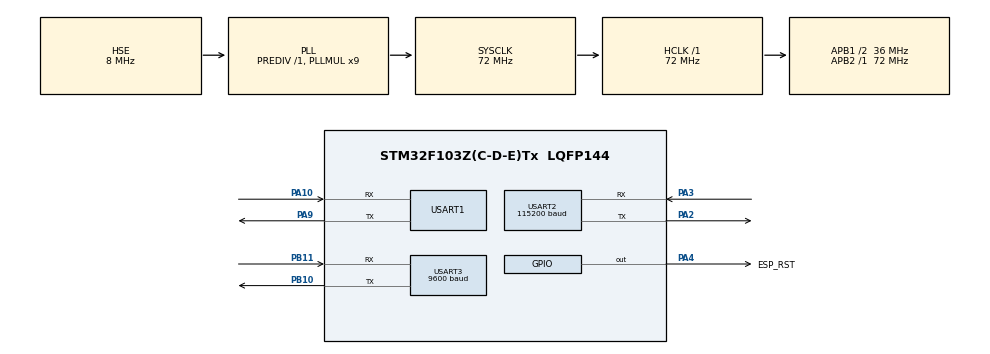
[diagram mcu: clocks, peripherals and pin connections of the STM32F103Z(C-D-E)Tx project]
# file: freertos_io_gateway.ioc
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FREERTOS.Tasks01=mbMasterTask,24,256,StartModbusMasterTask,As weak,NULL,Dynamic,NULL,NULL;mbRxTask,32,256,StartModbusRxTask,As external,NULL,Dynamic,NULL,NULL
Mcu.Family=STM32F1
Mcu.Name=STM32F103Z(C-D-E)Tx
Mcu.Package=LQFP144
NVIC.PriorityGroup=NVIC_PRIORITYGROUP_4
NVIC.TIM2_IRQn=true\:5\:0\:true\:false\:true\:true\:true\:true\:true
NVIC.TIM3_IRQn=true\:15\:0\:false\:false\:true\:false\:false\:true\:true
NVIC.TimeBase=TIM3_IRQn
NVIC.TimeBaseIP=TIM3
NVIC.USART2_IRQn=true\:5\:0\:true\:false\:true\:true\:true\:true\:true
NVIC.USART3_IRQn=true\:5\:0\:true\:false\:true\:true\:true\:true\:true
OSC_IN.Mode=HSE-External-Oscillator
OSC_IN.Signal=RCC_OSC_IN
OSC_OUT.Mode=HSE-External-Oscillator
OSC_OUT.Signal=RCC_OSC_OUT
PA10.Mode=Asynchronous
PA10.Signal=USART1_RX
PA13.Mode=Serial_Wire
PA13.Signal=SYS_JTMS-SWDIO
PA14.Mode=Serial_Wire
PA14.Signal=SYS_JTCK-SWCLK
PA2.Mode=Asynchronous
PA2.Signal=USART2_TX
PA3.Mode=Asynchronous
PA3.Signal=USART2_RX
PA4.GPIO_Label=ESP_RST
PA4.PinState=GPIO_PIN_SET
PA4.Signal=GPIO_Output
PA9.Mode=Asynchronous
PA9.Signal=USART1_TX
PB10.Mode=Asynchronous
PB10.Signal=USART3_TX
PB11.Mode=Asynchronous
PB11.Signal=USART3_RX
PC14-OSC32_IN.Mode=LSE-External-Oscillator
PC14-OSC32_IN.Signal=RCC_OSC32_IN
PC15-OSC32_OUT.Mode=LSE-External-Oscillator
PC15-OSC32_OUT.Signal=RCC_OSC32_OUT
ProjectManager.HeapSize=0x200
ProjectManager.StackSize=0x400
ProjectManager.TargetToolchain=CMake
RCC.AHBFreq_Value=72000000
RCC.APB1CLKDivider=RCC_HCLK_DIV2
RCC.APB1Freq_Value=36000000
RCC.APB1TimFreq_Value=72000000
RCC.APB2Freq_Value=72000000
RCC.APB2TimFreq_Value=72000000
RCC.HCLKFreq_Value=72000000
RCC.PLLMUL=RCC_PLL_MUL9
RCC.PLLSourceVirtual=RCC_PLLSOURCE_HSE
RCC.SYSCLKFreq_VALUE=72000000
RCC.SYSCLKSource=RCC_SYSCLKSOURCE_PLLCLK
RCC.USBFreq_Value=72000000
TIM2.Period=999
TIM2.Prescaler=71
USART1.VirtualMode=VM_ASYNC
USART2.BaudRate=115200
USART2.VirtualMode=VM_ASYNC
USART3.BaudRate=9600
USART3.VirtualMode=VM_ASYNC
VP_FREERTOS_VS_CMSIS_V2.Mode=CMSIS_V2
VP_SYS_VS_tim3.Mode=TIM3
VP_TIM2_VS_ClockSourceINT.Mode=Internal
board=custom

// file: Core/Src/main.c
/* USER CODE BEGIN Header */
/**
  ******************************************************************************
  * @file           : main.c
  * @brief          : Main program body
  ******************************************************************************
  * @attention
  *
  * Copyright (c) 2026 STMicroelectronics.
  * All rights reserved.
  *
  * This software is licensed under terms that can be found in the LICENSE file
  * in the root directory of this software component.
  * If no LICENSE file comes with this software, it is provided AS-IS.
  *
  ******************************************************************************
  */
/* USER CODE END Header */
#include "main.h"
#include "cmsis_os.h"
#include "tim.h"
#include "usart.h"
#include "gpio.h"

/* USER CODE BEGIN Includes */
#include "modbus_service.h"
#include "esp8266_task.h"

/* USER CODE END Includes */

void SystemClock_Config(void);
void MX_FREERTOS_Init(void);

int main(void)
{

  /* MCU Configuration--------------------------------------------------------*/

  /* Reset of all peripherals, Initializes the Flash interface and the Systick. */
  HAL_Init();

  /* Configure the system clock */
  SystemClock_Config();

  /* Initialize all configured peripherals */
  MX_GPIO_Init();
  MX_TIM2_Init();
  MX_USART1_UART_Init();
  MX_USART2_UART_Init();
  MX_USART3_UART_Init();

  /* Init scheduler */
  osKernelInitialize();  /* Call init function for freertos objects (in cmsis_os2.c) */
  MX_FREERTOS_Init();

  /* Start scheduler */
  osKernelStart();

  /* We should never get here as control is now taken by the scheduler */

  /* Infinite loop */
  while (1)
  {

  }
}

void SystemClock_Config(void)
{
  RCC_OscInitTypeDef RCC_OscInitStruct = {0};
  RCC_ClkInitTypeDef RCC_ClkInitStruct = {0};

  /** Initializes the RCC Oscillators according to the specified parameters
  * in the RCC_OscInitTypeDef structure.
  */
  RCC_OscInitStruct.OscillatorType = RCC_OSCILLATORTYPE_HSE;
  RCC_OscInitStruct.HSEState = RCC_HSE_ON;
  RCC_OscInitStruct.HSEPredivValue = RCC_HSE_PREDIV_DIV1;
  RCC_OscInitStruct.HSIState = RCC_HSI_ON;
  RCC_OscInitStruct.PLL.PLLState = RCC_PLL_ON;
  RCC_OscInitStruct.PLL.PLLSource = RCC_PLLSOURCE_HSE;
  RCC_OscInitStruct.PLL.PLLMUL = RCC_PLL_MUL9;
  if (HAL_RCC_OscConfig(&RCC_OscInitStruct) != HAL_OK)
  {
    Error_Handler();
  }

  /** Initializes the CPU, AHB and APB buses clocks
  */
  RCC_ClkInitStruct.ClockType = RCC_CLOCKTYPE_HCLK|RCC_CLOCKTYPE_SYSCLK
                              |RCC_CLOCKTYPE_PCLK1|RCC_CLOCKTYPE_PCLK2;
  RCC_ClkInitStruct.SYSCLKSource = RCC_SYSCLKSOURCE_PLLCLK;
  RCC_ClkInitStruct.AHBCLKDivider = RCC_SYSCLK_DIV1;
  RCC_ClkInitStruct.APB1CLKDivider = RCC_HCLK_DIV2;
  RCC_ClkInitStruct.APB2CLKDivider = RCC_HCLK_DIV1;

  if (HAL_RCC_ClockConfig(&RCC_ClkInitStruct, FLASH_LATENCY_2) != HAL_OK)
  {
    Error_Handler();
  }
}

/* USER CODE BEGIN 4 */
void HAL_UART_RxCpltCallback(UART_HandleTypeDef *huart)
{
  Modbus_Service_OnUartRxCplt(huart);
  Esp8266_OnUartRxCplt(huart);
}

/* USER CODE END 4 */

void HAL_TIM_PeriodElapsedCallback(TIM_HandleTypeDef *htim)
{
  if (htim->Instance == TIM3)
  {
    HAL_IncTick();
  }
  /* USER CODE BEGIN Callback 1 */
  Modbus_Service_OnTimPeriodElapsed(htim);

  /* USER CODE END Callback 1 */
}

void Error_Handler(void)
{
  __disable_irq();
  while (1)
  {
  }
}

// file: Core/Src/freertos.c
/* USER CODE BEGIN Header */
/**
  ******************************************************************************
  * File Name          : freertos.c
  * Description        : Code for freertos applications
  ******************************************************************************
  * @attention
  *
  * Copyright (c) 2026 STMicroelectronics.
  * All rights reserved.
  *
  * This software is licensed under terms that can be found in the LICENSE file
  * in the root directory of this software component.
  * If no LICENSE file comes with this software, it is provided AS-IS.
  *
  ******************************************************************************
  */
/* USER CODE END Header */

#include "FreeRTOS.h"
#include "task.h"
#include "main.h"
#include "cmsis_os.h"

/* USER CODE BEGIN Includes */
#include "modbus_service.h"
#include "gateway_task.h"
#include "esp8266_task.h"
/* USER CODE END Includes */

/* Definitions for mbMasterTask */
osThreadId_t mbMasterTaskHandle;
const osThreadAttr_t mbMasterTask_attributes = {
  .name = "mbMasterTask",
  .stack_size = 256 * 4,
  .priority = (osPriority_t) osPriorityNormal,
};
/* Definitions for mbRxTask */
osThreadId_t mbRxTaskHandle;
const osThreadAttr_t mbRxTask_attributes = {
  .name = "mbRxTask",
  .stack_size = 256 * 4,
  .priority = (osPriority_t) osPriorityAboveNormal,
};

void StartModbusMasterTask(void *argument);
extern void StartModbusRxTask(void *argument);

void MX_FREERTOS_Init(void); /* (MISRA C 2004 rule 8.1) */

void MX_FREERTOS_Init(void) {
  /* USER CODE BEGIN Init */
  Modbus_Service_Init();
  GatewayTask_Init();
  Esp8266_Init();
  /* USER CODE END Init */

  /* Create the thread(s) */
  /* creation of mbMasterTask */
  mbMasterTaskHandle = osThreadNew(StartModbusMasterTask, NULL, &mbMasterTask_attributes);

  /* creation of mbRxTask */
  mbRxTaskHandle = osThreadNew(StartModbusRxTask, NULL, &mbRxTask_attributes);

  /* USER CODE BEGIN RTOS_THREADS */
  /* add threads, ... */
  Esp8266_StartTask();
  /* USER CODE END RTOS_THREADS */

}

__weak void StartModbusMasterTask(void *argument)
{
  for(;;)
  {
    osDelay(1);
  }
}
